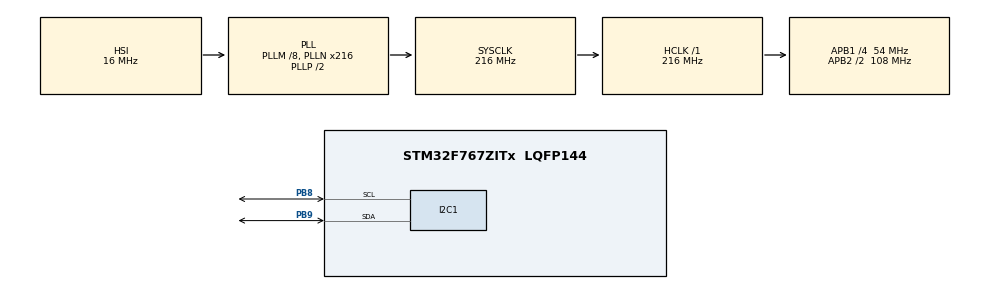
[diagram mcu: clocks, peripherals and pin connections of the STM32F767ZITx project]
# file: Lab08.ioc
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I2C1.Timing=0x20404768
Mcu.Family=STM32F7
Mcu.Name=STM32F767ZITx
Mcu.Package=LQFP144
NVIC.PriorityGroup=NVIC_PRIORITYGROUP_4
PB8.Mode=I2C
PB8.Signal=I2C1_SCL
PB9.Mode=I2C
PB9.Signal=I2C1_SDA
ProjectManager.HeapSize=0x200
ProjectManager.StackSize=0x400
ProjectManager.TargetToolchain=STM32CubeIDE
RCC.AHBFreq_Value=216000000
RCC.APB1CLKDivider=RCC_HCLK_DIV4
RCC.APB1Freq_Value=54000000
RCC.APB1TimFreq_Value=108000000
RCC.APB2CLKDivider=RCC_HCLK_DIV2
RCC.APB2Freq_Value=108000000
RCC.APB2TimFreq_Value=216000000
RCC.CortexFreq_Value=216000000
RCC.HCLKFreq_Value=216000000
RCC.HSE_VALUE=25000000
RCC.HSI_VALUE=16000000
RCC.LSE_VALUE=32768
RCC.PLLM=8
RCC.PLLN=216
RCC.SYSCLKFreq_VALUE=216000000
RCC.SYSCLKSource=RCC_SYSCLKSOURCE_PLLCLK
RCC.USBFreq_Value=216000000
RCC.VCOOutputFreq_Value=432000000
board=custom

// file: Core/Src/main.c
/* USER CODE BEGIN Header */
/**
  ******************************************************************************
  * @file           : main.c
  * @brief          : Main program body
  ******************************************************************************
  * @attention
  *
  * Copyright (c) 2023 STMicroelectronics.
  * All rights reserved.
  *
  * This software is licensed under terms that can be found in the LICENSE file
  * in the root directory of this software component.
  * If no LICENSE file comes with this software, it is provided AS-IS.
  *
  ******************************************************************************
  */
/* USER CODE END Header */
#include "main.h"
#include "i2c.h"
#include "gpio.h"

/* USER CODE BEGIN Includes */
#include "string.h"
/* USER CODE END Includes */

/* USER CODE BEGIN PV */
float h, t; //declear humiduty and temperature variable
uint8_t step;
HAL_StatusTypeDef status;
uint8_t cmdBuffer[3];
uint8_t dataBuffer[8];
/* USER CODE END PV */

void SystemClock_Config(void);
/* USER CODE BEGIN PFP */
uint16_t CRC16_2(uint8_t *, uint8_t);
void readSensor(void);
/* USER CODE END PFP */

int main(void)
{

  /* MCU Configuration--------------------------------------------------------*/

  /* Reset of all peripherals, Initializes the Flash interface and the Systick. */
  HAL_Init();

  /* Configure the system clock */
  SystemClock_Config();

  /* Initialize all configured peripherals */
  MX_GPIO_Init();
  MX_I2C1_Init();
  /* USER CODE BEGIN 2 */
  cmdBuffer[0] = 0x03;
  cmdBuffer[1] = 0x00;
  cmdBuffer[2] = 0x04;
  /* USER CODE END 2 */

  /* Infinite loop */
  while (1)
  {
	  readSensor();
  }
}

void SystemClock_Config(void)
{
  RCC_OscInitTypeDef RCC_OscInitStruct = {0};
  RCC_ClkInitTypeDef RCC_ClkInitStruct = {0};

  /** Configure the main internal regulator output voltage
  */
  __HAL_RCC_PWR_CLK_ENABLE();
  __HAL_PWR_VOLTAGESCALING_CONFIG(PWR_REGULATOR_VOLTAGE_SCALE1);

  /** Initializes the RCC Oscillators according to the specified parameters
  * in the RCC_OscInitTypeDef structure.
  */
  RCC_OscInitStruct.OscillatorType = RCC_OSCILLATORTYPE_HSI;
  RCC_OscInitStruct.HSIState = RCC_HSI_ON;
  RCC_OscInitStruct.HSICalibrationValue = RCC_HSICALIBRATION_DEFAULT;
  RCC_OscInitStruct.PLL.PLLState = RCC_PLL_ON;
  RCC_OscInitStruct.PLL.PLLSource = RCC_PLLSOURCE_HSI;
  RCC_OscInitStruct.PLL.PLLM = 8;
  RCC_OscInitStruct.PLL.PLLN = 216;
  RCC_OscInitStruct.PLL.PLLP = RCC_PLLP_DIV2;
  RCC_OscInitStruct.PLL.PLLQ = 2;
  RCC_OscInitStruct.PLL.PLLR = 2;
  if (HAL_RCC_OscConfig(&RCC_OscInitStruct) != HAL_OK)
  {
    Error_Handler();
  }

  /** Activate the Over-Drive mode
  */
  if (HAL_PWREx_EnableOverDrive() != HAL_OK)
  {
    Error_Handler();
  }

  /** Initializes the CPU, AHB and APB buses clocks
  */
  RCC_ClkInitStruct.ClockType = RCC_CLOCKTYPE_HCLK|RCC_CLOCKTYPE_SYSCLK
                              |RCC_CLOCKTYPE_PCLK1|RCC_CLOCKTYPE_PCLK2;
  RCC_ClkInitStruct.SYSCLKSource = RCC_SYSCLKSOURCE_PLLCLK;
  RCC_ClkInitStruct.AHBCLKDivider = RCC_SYSCLK_DIV1;
  RCC_ClkInitStruct.APB1CLKDivider = RCC_HCLK_DIV4;
  RCC_ClkInitStruct.APB2CLKDivider = RCC_HCLK_DIV2;

  if (HAL_RCC_ClockConfig(&RCC_ClkInitStruct, FLASH_LATENCY_7) != HAL_OK)
  {
    Error_Handler();
  }
}

/* USER CODE BEGIN 4 */
uint16_t CRC16_2(uint8_t *ptr, uint8_t length)
{
	uint16_t crc = 0xFFFF;
	uint8_t s = 0x00;

	while (length--) {
		crc ^= *ptr++;
		for (s = 0; s < 8; s++) {
			if ((crc & 0x01) != 0) {
				crc >>= 1;
				crc ^= 0xA001;
			}
			else crc >>= 1;
		}
	}
	return crc;
}
void readSensor(void)
{
	HAL_I2C_Master_Transmit(&hi2c1, 0x5c<<1, cmdBuffer, 3, 200); //wake up sensor
	HAL_I2C_Master_Transmit(&hi2c1, 0x5c<<1, cmdBuffer, 3, 200); //send reading command
	HAL_Delay(1);
	HAL_I2C_Master_Receive(&hi2c1, 0x5c<<1, dataBuffer, 8, 200); //receive sensor data
	uint16_t Rcrc = dataBuffer[7] << 8;
	Rcrc += dataBuffer[6];
	if (Rcrc == CRC16_2(dataBuffer, 6)){
		uint16_t temperature = ((dataBuffer[4] & 0x7F) << 8) + dataBuffer[5];
		t = temperature / 10.0;
		t = ((dataBuffer[4] & 0x80) >> 7 == 1) ? (t * (-1)) : t;

		uint16_t humidity = (dataBuffer[2] << 8) + dataBuffer[3];
		h = humidity / 10.0;
	}
}
/* USER CODE END 4 */

void Error_Handler(void)
{
  __disable_irq();
  while (1)
  {
  }
}
